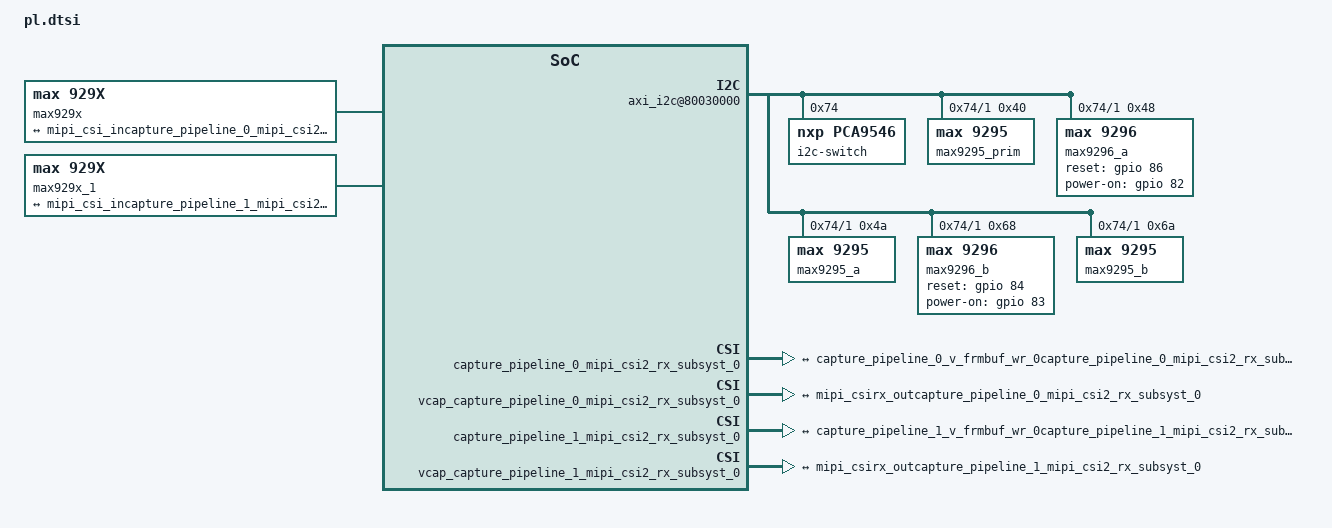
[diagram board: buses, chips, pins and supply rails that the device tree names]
/*
 * CAUTION: This file is automatically generated by Xilinx.
 * Version:
 * Today is: Sat Dec 25 10:05:39 2021
 */


/dts-v1/;
/plugin/;

/ {
	fragment@0 {
		target = <&fpga_full>;
		overlay0: __overlay__ {
			#address-cells = <2>;
			#size-cells = <2>;
			firmware-name = "k26heimdallr.bit.bin";
			resets = <&zynqmp_reset 116>, <&zynqmp_reset 117>, <&zynqmp_reset 118>, <&zynqmp_reset 119>;
		};
	};
	fragment@1 {
		target = <&amba>;
		overlay1: __overlay__ {
			afi0: afi0 {
				compatible = "xlnx,afi-fpga";
				config-afi = < 0 0>, <1 0>, <2 0>, <3 0>, <4 0>, <5 0>, <6 0>, <7 0>, <8 0>, <9 0>, <10 0>, <11 0>, <12 0>, <13 0>, <14 0x0>, <15 0x000>;
			};
			clocking0: clocking0 {
				#clock-cells = <0>;
				assigned-clock-rates = <99999001>;
				assigned-clocks = <&zynqmp_clk 71>;
				clock-output-names = "fabric_clk";
				clocks = <&zynqmp_clk 71>;
				compatible = "xlnx,fclk";
			};
			clocking1: clocking1 {
				#clock-cells = <0>;
				assigned-clock-rates = <99999001>;
				assigned-clocks = <&zynqmp_clk 72>;
				clock-output-names = "fabric_clk";
				clocks = <&zynqmp_clk 72>;
				compatible = "xlnx,fclk";
			};
		};
	};
	fragment@2 {
		target = <&amba>;
		overlay2: __overlay__ {
			#address-cells = <2>;
			#size-cells = <2>;
			Trigger_0: Trigger@80200000 {
				clock-names = "s_axi_aclk";
				clocks = <&misc_clk_0>;
				compatible = "xlnx,Trigger-1.0";
				reg = <0x0 0x80200000 0x0 0x10000>;
			};

			misc_clk_0: misc_clk_0 {
				#clock-cells = <0>;
				clock-frequency = <99999000>;
				compatible = "fixed-clock";
			};
			misc_clk_1: misc_clk_1 {
				#clock-cells = <0>;
				clock-frequency = <199998000>;
				compatible = "fixed-clock";
			};

			misc_clk_2: misc_clk_2 {
				#clock-cells = <0>;
				clock-frequency = <299997000>;
				compatible = "fixed-clock";
			};


			axi_i2c@80030000 {
				#address-cells = <1>;
				#size-cells = <0>;
				clock-names = "s_axi_aclk";
				clocks = <&misc_clk_0>;
				compatible = "xlnx,axi-iic-2.0", "xlnx,xps-iic-2.00.a";
				interrupt-names = "iic2intc_irpt";
				interrupt-parent = <&gic>;
				interrupts = <0 107 4>;
				reg = <0x0 0x80030000 0x0 0x10000>;
			        status = "okay";

				i2c-switch@74 {
					compatible = "nxp,pca9546";
					#address-cells = <0x01>;
					#size-cells = <0x00>;
					reg = <0x74>;

					i2c@0 {
						#address-cells = <0x00>;
						#size-cells = <0x00>;
						reg = <0x01>;
					};

					i2c@1 {
						#address-cells = <0x01>;
						#size-cells = <0x00>;
						reg = <0x01>;

						max9295_prim@40 {
							reg = <0x40>;
							compatible = "max,9295";
						};

						max9296_a@48 {
							reg = <0x48>;
							compatible = "max,9296";

							reset-gpio = <&gpio 86 0>;
							power-on-gpio = <&gpio 82 0>;

						};

						max9295_a@4a {
							reg = <0x4a>;
							compatible = "max,9295";
						};


						max9296_b@68 {
							reg = <0x68>;
							compatible = "max,9296";

							reset-gpio = <&gpio 84 0>;
							power-on-gpio = <&gpio 83 0>;

						};

						max9295_b@6a {
							reg = <0x6a>;
							compatible = "max,9295";
						};

					};

				};
			};

////////////////////////////////////////////mipi_0/////////////////////////////////////////
			max929x: max929x_0 {
				compatible = "max,929x";
			        status = "okay";

				max9296_i2c_addr = /bits/ 8 <0x48>;
      				max9295_i2c_addr = /bits/ 8 <0x4a>;

				ports {
					#address-cells = <1>;
					#size-cells = <0>;
					port@1 {
						reg = <1>;
						max929x_out: endpoint {
							remote-endpoint = <&mipi_csi_incapture_pipeline_0_mipi_csi2_rx_subsyst_0>;
							data-lanes = <1 2 3 4>;
						};
					};
				};
			};


			capture_pipeline_0_mipi_csi2_rx_subsyst_0: mipi_csi2_rx_subsystem@80000000 {
				clock-names = "lite_aclk", "dphy_clk_200M", "video_aclk";
				clocks = <&misc_clk_0>, <&misc_clk_1>, <&misc_clk_2>;
				compatible = "xlnx,mipi-csi2-rx-subsystem-5.1", "xlnx,mipi-csi2-rx-subsystem-5.0";
				interrupt-names = "csirxss_csi_irq";
				interrupt-parent = <&gic>;
				interrupts = <0 104 4>;
				reg = <0x0 0x80000000 0x0 0x1000>;
				xlnx,axis-tdata-width = <32>;
				xlnx,max-lanes = <4>;
				xlnx,ppc = <2>;
				xlnx,vfb ;
				xlnx,csi-pxl-format = <0x1e>;
				mipi_csi_portscapture_pipeline_0_mipi_csi2_rx_subsyst_0: ports {
					#address-cells = <1>;
					#size-cells = <0>;
					mipi_csi_port0capture_pipeline_0_mipi_csi2_rx_subsyst_0: port@1 {
						reg = <1>;
						xlnx,video-format = <0>;
						xlnx,video-width = <8>;
						mipi_csirx_outcapture_pipeline_0_mipi_csi2_rx_subsyst_0: endpoint {
							remote-endpoint = <&capture_pipeline_0_v_frmbuf_wr_0capture_pipeline_0_mipi_csi2_rx_subsyst_0>;
						};
					};
					mipi_csi_port1capture_pipeline_0_mipi_csi2_rx_subsyst_0: port@0 {
						reg = <0>;
						xlnx,video-format = <0>;
						xlnx,video-width = <8>;
						mipi_csi_incapture_pipeline_0_mipi_csi2_rx_subsyst_0: endpoint {
							data-lanes = <1 2 3 4>;
							remote-endpoint = <&max929x_out>;
						};
					};
				};
			};

			capture_pipeline_0_v_frmbuf_wr_0: v_frmbuf_wr@b0010000 {
				#dma-cells = <1>;
				clock-names = "ap_clk";
				clocks = <&misc_clk_2>;
				compatible = "xlnx,v-frmbuf-wr-2.2", "xlnx,axi-frmbuf-wr-v2.1";
				interrupt-names = "interrupt";
				interrupt-parent = <&gic>;
				interrupts = <0 105 4>;
				reg = <0x0 0xb0010000 0x0 0x10000>;
				reset-gpios = <&gpio 88 1>;
				xlnx,dma-addr-width = <32>;
				xlnx,dma-align = <16>;
				xlnx,max-height = <2160>;
				xlnx,max-width = <3840>;
				xlnx,pixels-per-clock = <2>;
				xlnx,s-axi-ctrl-addr-width = <0x7>;
				xlnx,s-axi-ctrl-data-width = <0x20>;
				xlnx,vid-formats = "uyvy", "yuyv";
				//xlnx,video-width = <8>;
			};

			vcap_capture_pipeline_0_mipi_csi2_rx_subsyst_0 {
				compatible = "xlnx,video";
				dma-names = "port0";
				dmas = <&capture_pipeline_0_v_frmbuf_wr_0 0>;
				vcap_portscapture_pipeline_0_mipi_csi2_rx_subsyst_0: ports {
					#address-cells = <1>;
					#size-cells = <0>;
					vcap_portcapture_pipeline_0_mipi_csi2_rx_subsyst_0: port@0 {
						direction = "input";
						reg = <0>;
						capture_pipeline_0_v_frmbuf_wr_0capture_pipeline_0_mipi_csi2_rx_subsyst_0: endpoint {
							remote-endpoint = <&mipi_csirx_outcapture_pipeline_0_mipi_csi2_rx_subsyst_0>;
						};
					};
				};
			};

////////////////////////////////////////////mipi_1/////////////////////////////////////////

			max929x_1: max929x_1 {
				compatible = "max,929x";
			        status = "okay";

      				max9296_i2c_addr = /bits/ 8 <0x68>;
      				max9295_i2c_addr = /bits/ 8 <0x6a>;

				ports {
					#address-cells = <1>;
					#size-cells = <0>;
					port@1 {
						reg = <1>;
						max929x_1_out: endpoint {
							remote-endpoint = <&mipi_csi_incapture_pipeline_1_mipi_csi2_rx_subsyst_0>;
							data-lanes = <1 2 3 4>;
						};
					};
				};
			};


			capture_pipeline_1_mipi_csi2_rx_subsyst_0: mipi_csi2_rx_subsystem@80010000 {
				clock-names = "lite_aclk", "dphy_clk_200M", "video_aclk";
				clocks = <&misc_clk_0>, <&misc_clk_1>, <&misc_clk_2>;
				compatible = "xlnx,mipi-csi2-rx-subsystem-5.1", "xlnx,mipi-csi2-rx-subsystem-5.0";
				interrupt-names = "csirxss_csi_irq";
				interrupt-parent = <&gic>;
				interrupts = <0 108 4>;
				reg = <0x0 0x80010000 0x0 0x1000>;
				xlnx,axis-tdata-width = <32>;
				xlnx,max-lanes = <4>;
				xlnx,ppc = <2>;
				xlnx,vfb ;
				xlnx,csi-pxl-format = <0x1e>;
				mipi_csi_portscapture_pipeline_1_mipi_csi2_rx_subsyst_0: ports {
					#address-cells = <1>;
					#size-cells = <0>;
					mipi_csi_port0capture_pipeline_1_mipi_csi2_rx_subsyst_0: port@1 {
						reg = <1>;
						xlnx,video-format = <0>;
						xlnx,video-width = <8>;
						mipi_csirx_outcapture_pipeline_1_mipi_csi2_rx_subsyst_0: endpoint {
							remote-endpoint = <&capture_pipeline_1_v_frmbuf_wr_0capture_pipeline_1_mipi_csi2_rx_subsyst_0>;
						};
					};
					mipi_csi_port1capture_pipeline_1_mipi_csi2_rx_subsyst_0: port@0 {
						reg = <0>;
						xlnx,video-format = <0>;
						xlnx,video-width = <8>;
						mipi_csi_incapture_pipeline_1_mipi_csi2_rx_subsyst_0: endpoint {
							data-lanes = <1 2 3 4>;
							remote-endpoint = <&max929x_1_out>;
						};
					};
				};
			};

			capture_pipeline_1_v_frmbuf_wr_0: v_frmbuf_wr@b0020000 {
				#dma-cells = <1>;
				clock-names = "ap_clk";
				clocks = <&misc_clk_2>;
				compatible = "xlnx,v-frmbuf-wr-2.2", "xlnx,axi-frmbuf-wr-v2.1";
				interrupt-names = "interrupt";
				interrupt-parent = <&gic>;
				interrupts = <0 109 4>;
				reg = <0x0 0xb0020000 0x0 0x10000>;
				reset-gpios = <&gpio 89 1>;
				xlnx,dma-addr-width = <32>;
				xlnx,dma-align = <16>;
				xlnx,max-height = <2160>;
				xlnx,max-width = <3840>;
				xlnx,pixels-per-clock = <2>;
				xlnx,s-axi-ctrl-addr-width = <0x7>;
				xlnx,s-axi-ctrl-data-width = <0x20>;
				xlnx,vid-formats = "uyvy", "yuyv";
				//xlnx,video-width = <8>;
			};

			vcap_capture_pipeline_1_mipi_csi2_rx_subsyst_0 {
				compatible = "xlnx,video";
				dma-names = "port0";
				dmas = <&capture_pipeline_1_v_frmbuf_wr_0 0>;
				vcap_portscapture_pipeline_1_mipi_csi2_rx_subsyst_0: ports {
					#address-cells = <1>;
					#size-cells = <0>;
					vcap_portcapture_pipeline_1_mipi_csi2_rx_subsyst_0: port@0 {
						direction = "input";
						reg = <0>;
						capture_pipeline_1_v_frmbuf_wr_0capture_pipeline_1_mipi_csi2_rx_subsyst_0: endpoint {
							remote-endpoint = <&mipi_csirx_outcapture_pipeline_1_mipi_csi2_rx_subsyst_0>;
						};
					};
				};
			};

			vcu_vcu_0: vcu@80100000 {
				#address-cells = <2>;
				#clock-cells = <1>;
				#size-cells = <2>;
				clock-names = "pll_ref", "aclk", "vcu_core_enc", "vcu_core_dec", "vcu_mcu_enc", "vcu_mcu_dec";
				clocks = <&misc_clk_3>, <&misc_clk_0>, <&vcu_vcu_0 1>, <&vcu_vcu_0 2>, <&vcu_vcu_0 3>, <&vcu_vcu_0 4>;
				compatible = "xlnx,vcu-1.2", "xlnx,vcu";
				interrupt-names = "vcu_host_interrupt";
				interrupt-parent = <&gic>;
				interrupts = <0 106 4>;
				ranges ;
				reg = <0x0 0x80140000 0x0 0x1000>, <0x0 0x80141000 0x0 0x1000>;
				reg-names = "vcu_slcr", "logicore";
				reset-gpios = <&gpio 80 0>;
				encoder: al5e@80100000 {
					compatible = "al,al5e-1.2", "al,al5e";
					interrupt-parent = <&gic>;
					interrupts = <0 106 4>;
					reg = <0x0 0x80100000 0x0 0x10000>;
				};
				decoder: al5d@80120000 {
					compatible = "al,al5d-1.2", "al,al5d";
					interrupt-parent = <&gic>;
					interrupts = <0 106 4>;
					reg = <0x0 0x80120000 0x0 0x10000>;
				};
			};
			misc_clk_3: misc_clk_3 {
				#clock-cells = <0>;
				clock-frequency = <49999500>;
				compatible = "fixed-clock";
			};
			zyxclmm_drm {
				compatible = "xlnx,zocl";
                                status = "okay";
                                interrupt-parent = <&gic>;
                                interrupts = <0x00 0x59 0x04 0x00 0x5a 0x04 0x00 0x5b 0x04 0x00 0x5c 0x04 0x00 0x5d 0x04 0x00 0x5e 0x04 0x00 0x5f 0x04 0x00 0x60 0x04>;
                                phandle = <0x1c>;
			};
		};
	};
};
